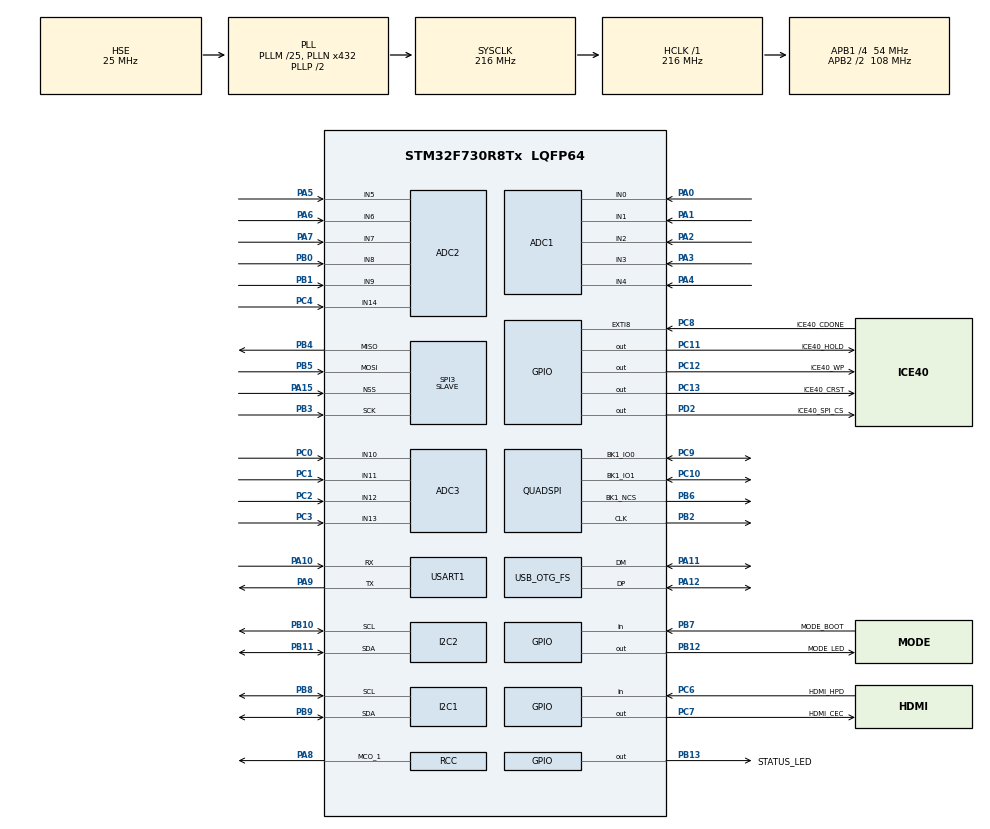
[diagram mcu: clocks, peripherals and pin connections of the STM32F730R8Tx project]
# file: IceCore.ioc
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ADC1.Channel-0\#ChannelRegularConversion=ADC_CHANNEL_0
ADC1.NbrOfConversionFlag=1
ADC1.Rank-0\#ChannelRegularConversion=1
ADC1.SamplingTime-0\#ChannelRegularConversion=ADC_SAMPLETIME_3CYCLES
ADC1.master=1
ADC2.Channel-6\#ChannelRegularConversion=ADC_CHANNEL_5
ADC2.NbrOfConversionFlag=1
ADC2.Rank-6\#ChannelRegularConversion=1
ADC2.SamplingTime-6\#ChannelRegularConversion=ADC_SAMPLETIME_3CYCLES
ADC3.Channel-0\#ChannelRegularConversion=ADC_CHANNEL_13
ADC3.NbrOfConversionFlag=1
ADC3.Rank-0\#ChannelRegularConversion=1
ADC3.SamplingTime-0\#ChannelRegularConversion=ADC_SAMPLETIME_3CYCLES
Dma.Request0=USART1_TX
Dma.USART1_TX.0.Direction=DMA_MEMORY_TO_PERIPH
Dma.USART1_TX.0.FIFOMode=DMA_FIFOMODE_DISABLE
Dma.USART1_TX.0.Instance=DMA2_Stream7
Dma.USART1_TX.0.MemDataAlignment=DMA_MDATAALIGN_BYTE
Dma.USART1_TX.0.MemInc=DMA_MINC_ENABLE
Dma.USART1_TX.0.Mode=DMA_NORMAL
Dma.USART1_TX.0.PeriphDataAlignment=DMA_PDATAALIGN_BYTE
Dma.USART1_TX.0.PeriphInc=DMA_PINC_DISABLE
Dma.USART1_TX.0.Priority=DMA_PRIORITY_LOW
I2C1.Timing=0x20404768
I2C2.Timing=0x20404768
Mcu.Family=STM32F7
Mcu.Name=STM32F730R8Tx
Mcu.Package=LQFP64
NVIC.DMA2_Stream7_IRQn=true\:1\:0\:true\:false\:true\:false
NVIC.OTG_FS_IRQn=true\:1\:0\:true\:false\:true\:false
NVIC.PriorityGroup=NVIC_PRIORITYGROUP_4
NVIC.TIM6_DAC_IRQn=true\:1\:0\:true\:false\:true\:true
NVIC.USART1_IRQn=true\:1\:0\:true\:false\:true\:true
PA0-WKUP.Signal=ADCx_IN0
PA1.Signal=ADCx_IN1
PA10.Mode=Asynchronous
PA10.Signal=USART1_RX
PA11.Mode=Device_Only
PA11.Signal=USB_OTG_FS_DM
PA12.Mode=Device_Only
PA12.Signal=USB_OTG_FS_DP
PA13.Mode=Serial_Wire
PA13.Signal=SYS_JTMS-SWDIO
PA14.Mode=Serial_Wire
PA14.Signal=SYS_JTCK-SWCLK
PA15.Mode=NSS_Signal_Hard_Input
PA15.Signal=SPI3_NSS
PA2.Signal=ADCx_IN2
PA3.Signal=ADCx_IN3
PA4.Signal=ADCx_IN4
PA5.Signal=ADCx_IN5
PA6.Signal=ADCx_IN6
PA7.Signal=ADCx_IN7
PA8.Mode=Clock-out-1
PA8.Signal=RCC_MCO_1
PA9.Mode=Asynchronous
PA9.Signal=USART1_TX
PB0.Signal=ADCx_IN8
PB1.Signal=ADCx_IN9
PB10.Mode=I2C
PB10.Signal=I2C2_SCL
PB11.Mode=I2C
PB11.Signal=I2C2_SDA
PB12.GPIO_Label=MODE_LED
PB12.Signal=GPIO_Output
PB13.GPIO_Label=STATUS_LED
PB13.Signal=GPIO_Output
PB2.Mode=Single Bank 1 2IOs
PB2.Signal=QUADSPI_CLK
PB3.Mode=Full_Duplex_Slave
PB3.Signal=SPI3_SCK
PB4.Mode=Full_Duplex_Slave
PB4.Signal=SPI3_MISO
PB5.Mode=Full_Duplex_Slave
PB5.Signal=SPI3_MOSI
PB6.Mode=Single Bank 1 2IOs
PB6.Signal=QUADSPI_BK1_NCS
PB7.GPIO_Label=MODE_BOOT
PB7.Signal=GPIO_Input
PB8.Mode=I2C
PB8.Signal=I2C1_SCL
PB9.Mode=I2C
PB9.Signal=I2C1_SDA
PC0.Signal=ADCx_IN10
PC1.Signal=ADCx_IN11
PC10.Mode=Single Bank 1 2IOs
PC10.Signal=QUADSPI_BK1_IO1
PC11.GPIO_Label=ICE40_HOLD
PC11.GPIO_ModeDefaultOutputPP=GPIO_MODE_OUTPUT_OD
PC11.Signal=GPIO_Output
PC12.GPIO_Label=ICE40_WP
PC12.GPIO_ModeDefaultOutputPP=GPIO_MODE_OUTPUT_OD
PC12.Signal=GPIO_Output
PC13.GPIO_Label=ICE40_CRST
PC13.Signal=GPIO_Output
PC14-OSC32_IN.Mode=LSE-External-Oscillator
PC14-OSC32_IN.Signal=RCC_OSC32_IN
PC15-OSC32_OUT.Mode=LSE-External-Oscillator
PC15-OSC32_OUT.Signal=RCC_OSC32_OUT
PC2.Signal=ADCx_IN12
PC3.Signal=ADCx_IN13
PC4.Signal=ADCx_IN14
PC6.GPIO_Label=HDMI_HPD
PC6.GPIO_PuPd=GPIO_PULLDOWN
PC6.Signal=GPIO_Input
PC7.GPIO_Label=HDMI_CEC
PC7.Signal=GPIO_Output
PC8.GPIO_Label=ICE40_CDONE
PC8.GPIO_ModeDefaultEXTI=GPIO_MODE_IT_RISING_FALLING
PC8.Signal=GPXTI8
PC9.Mode=Single Bank 1 2IOs
PC9.Signal=QUADSPI_BK1_IO0
PD2.GPIO_Label=ICE40_SPI_CS
PD2.GPIO_ModeDefaultOutputPP=GPIO_MODE_OUTPUT_OD
PD2.Signal=GPIO_Output
PH0-OSC_IN.Mode=HSE-External-Oscillator
PH0-OSC_IN.Signal=RCC_OSC_IN
PH1-OSC_OUT.Mode=HSE-External-Oscillator
PH1-OSC_OUT.Signal=RCC_OSC_OUT
ProjectManager.HeapSize=0x000
ProjectManager.StackSize=0x400
ProjectManager.TargetToolchain=Makefile
QUADSPI.ClockPrescaler=2
RCC.AHBFreq_Value=216000000
RCC.APB1CLKDivider=RCC_HCLK_DIV4
RCC.APB1Freq_Value=54000000
RCC.APB1TimFreq_Value=108000000
RCC.APB2CLKDivider=RCC_HCLK_DIV2
RCC.APB2Freq_Value=108000000
RCC.APB2TimFreq_Value=216000000
RCC.CortexFreq_Value=216000000
RCC.HCLKFreq_Value=216000000
RCC.HSE_VALUE=25000000
RCC.HSI_VALUE=16000000
RCC.PLLM=25
RCC.PLLN=432
RCC.PLLQ=9
RCC.RCC_MCO1Source=RCC_MCO1SOURCE_HSE
RCC.SYSCLKFreq_VALUE=216000000
RCC.SYSCLKSource=RCC_SYSCLKSOURCE_PLLCLK
RCC.USBFreq_Value=48000000
RCC.VCOOutputFreq_Value=432000000
SH.ADCx_IN0.0=ADC1_IN0,IN0
SH.ADCx_IN1.0=ADC1_IN1,IN1
SH.ADCx_IN10.0=ADC3_IN10,IN10
SH.ADCx_IN11.0=ADC3_IN11,IN11
SH.ADCx_IN12.0=ADC3_IN12,IN12
SH.ADCx_IN13.0=ADC3_IN13,IN13
SH.ADCx_IN14.0=ADC2_IN14,IN14
SH.ADCx_IN2.0=ADC1_IN2,IN2
SH.ADCx_IN3.0=ADC1_IN3,IN3
SH.ADCx_IN4.0=ADC1_IN4,IN4
SH.ADCx_IN5.0=ADC2_IN5,IN5
SH.ADCx_IN6.0=ADC2_IN6,IN6
SH.ADCx_IN7.0=ADC2_IN7,IN7
SH.ADCx_IN8.0=ADC2_IN8,IN8
SH.ADCx_IN9.0=ADC2_IN9,IN9
SPI3.DataSize=SPI_DATASIZE_8BIT
SPI3.Direction=SPI_DIRECTION_2LINES
SPI3.Mode=SPI_MODE_SLAVE
SPI3.VirtualNSS=VM_NSSHARD
SPI3.VirtualType=VM_SLAVE
TIM6.AutoReloadPreload=TIM_AUTORELOAD_PRELOAD_ENABLE
TIM6.Period=20000
TIM6.Prescaler=7
USART1.VirtualMode-Asynchronous=VM_ASYNC
USB_DEVICE.CLASS_NAME_FS=CDC
USB_DEVICE.CLASS_NAME_HS=CDC
USB_DEVICE.VirtualMode-CDC_FS=Cdc
USB_DEVICE.VirtualMode-CDC_HS=Cdc
USB_DEVICE.VirtualModeFS=Cdc_FS
USB_DEVICE.VirtualModeHS=Cdc_HS
USB_OTG_FS.VirtualMode=Device_Only
VP_CRC_VS_CRC.Mode=CRC_Activate
VP_RTC_VS_RTC_Activate.Mode=RTC_Enabled
VP_RTC_VS_RTC_Calendar.Mode=RTC_Calendar
VP_TIM6_VS_ClockSourceINT.Mode=Enable_Timer
VP_USB_DEVICE_VS_USB_DEVICE_CDC_FS.Mode=CDC_FS
board=custom

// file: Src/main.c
/* USER CODE BEGIN Header */
/**
  ******************************************************************************
  * @file           : main.c
  * @brief          : Main program body
  ******************************************************************************
  ** This notice applies to any and all portions of this file
  * that are not between comment pairs USER CODE BEGIN and
  * USER CODE END. Other portions of this file, whether
  * inserted by the user or by software development tools
  * are owned by their respective copyright owners.
  *
  * COPYRIGHT(c) 2019 STMicroelectronics
  *
  * Redistribution and use in source and binary forms, with or without modification,
  * are permitted provided that the following conditions are met:
  *   1. Redistributions of source code must retain the above copyright notice,
  *      this list of conditions and the following disclaimer.
  *   2. Redistributions in binary form must reproduce the above copyright notice,
  *      this list of conditions and the following disclaimer in the documentation
  *      and/or other materials provided with the distribution.
  *   3. Neither the name of STMicroelectronics nor the names of its contributors
  *      may be used to endorse or promote products derived from this software
  *      without specific prior written permission.
  *
  * THIS SOFTWARE IS PROVIDED BY THE COPYRIGHT HOLDERS AND CONTRIBUTORS "AS IS"
  * AND ANY EXPRESS OR IMPLIED WARRANTIES, INCLUDING, BUT NOT LIMITED TO, THE
  * IMPLIED WARRANTIES OF MERCHANTABILITY AND FITNESS FOR A PARTICULAR PURPOSE ARE
  * DISCLAIMED. IN NO EVENT SHALL THE COPYRIGHT HOLDER OR CONTRIBUTORS BE LIABLE
  * FOR ANY DIRECT, INDIRECT, INCIDENTAL, SPECIAL, EXEMPLARY, OR CONSEQUENTIAL
  * DAMAGES (INCLUDING, BUT NOT LIMITED TO, PROCUREMENT OF SUBSTITUTE GOODS OR
  * SERVICES; LOSS OF USE, DATA, OR PROFITS; OR BUSINESS INTERRUPTION) HOWEVER
  * CAUSED AND ON ANY THEORY OF LIABILITY, WHETHER IN CONTRACT, STRICT LIABILITY,
  * OR TORT (INCLUDING NEGLIGENCE OR OTHERWISE) ARISING IN ANY WAY OUT OF THE USE
  * OF THIS SOFTWARE, EVEN IF ADVISED OF THE POSSIBILITY OF SUCH DAMAGE.
  *
  ******************************************************************************
  */
/* USER CODE END Header */

#include "main.h"
#include "usb_device.h"

ADC_HandleTypeDef hadc1;
ADC_HandleTypeDef hadc2;
ADC_HandleTypeDef hadc3;

CRC_HandleTypeDef hcrc;

I2C_HandleTypeDef hi2c1;
I2C_HandleTypeDef hi2c2;

QSPI_HandleTypeDef hqspi;

RTC_HandleTypeDef hrtc;

SPI_HandleTypeDef hspi3;

TIM_HandleTypeDef htim6;

UART_HandleTypeDef huart1;

PCD_HandleTypeDef hpcd_USB_OTG_HS;

void SystemClock_Config(void);
static void MX_GPIO_Init(void);
static void MX_USB_OTG_HS_PCD_Init(void);
static void MX_QUADSPI_Init(void);
static void MX_CRC_Init(void);
static void MX_I2C1_Init(void);
static void MX_ADC1_Init(void);
static void MX_ADC2_Init(void);
static void MX_ADC3_Init(void);
static void MX_SPI3_Init(void);
static void MX_USART1_UART_Init(void);
static void MX_I2C2_Init(void);
static void MX_RTC_Init(void);
static void MX_TIM6_Init(void);
/* USER CODE BEGIN PFP */
/* Private function prototypes -----------------------------------------------*/
extern void setup(void);
extern void loop(void);
/* USER CODE END PFP */

int main(void)
{

  /* MCU Configuration--------------------------------------------------------*/

  /* Reset of all peripherals, Initializes the Flash interface and the Systick. */
  HAL_Init();

  /* Configure the system clock */
  SystemClock_Config();

  /* Initialize all configured peripherals */
  MX_GPIO_Init();
  MX_USB_OTG_HS_PCD_Init();
  MX_QUADSPI_Init();
  MX_CRC_Init();
  MX_I2C1_Init();
  MX_ADC1_Init();
  MX_ADC2_Init();
  MX_ADC3_Init();
  MX_SPI3_Init();
  MX_USART1_UART_Init();
  MX_I2C2_Init();
  MX_USB_DEVICE_Init();
  MX_RTC_Init();
  MX_TIM6_Init();
  /* USER CODE BEGIN 2 */
  setup();
  /* USER CODE END 2 */

  /* Infinite loop */
  while (1)
  {

  }
}

void SystemClock_Config(void)
{
  RCC_OscInitTypeDef RCC_OscInitStruct = {0};
  RCC_ClkInitTypeDef RCC_ClkInitStruct = {0};
  RCC_PeriphCLKInitTypeDef PeriphClkInitStruct = {0};

  /**Configure LSE Drive Capability
  */
  HAL_PWR_EnableBkUpAccess();
  /**Configure the main internal regulator output voltage
  */
  __HAL_RCC_PWR_CLK_ENABLE();
  __HAL_PWR_VOLTAGESCALING_CONFIG(PWR_REGULATOR_VOLTAGE_SCALE1);
  /**Initializes the CPU, AHB and APB busses clocks
  */
  RCC_OscInitStruct.OscillatorType = RCC_OSCILLATORTYPE_LSI|RCC_OSCILLATORTYPE_HSE;
  RCC_OscInitStruct.HSEState = RCC_HSE_ON;
  RCC_OscInitStruct.LSIState = RCC_LSI_ON;
  RCC_OscInitStruct.PLL.PLLState = RCC_PLL_ON;
  RCC_OscInitStruct.PLL.PLLSource = RCC_PLLSOURCE_HSE;
  RCC_OscInitStruct.PLL.PLLM = 25;
  RCC_OscInitStruct.PLL.PLLN = 432;
  RCC_OscInitStruct.PLL.PLLP = RCC_PLLP_DIV2;
  RCC_OscInitStruct.PLL.PLLQ = 9;
  if (HAL_RCC_OscConfig(&RCC_OscInitStruct) != HAL_OK)
  {
    Error_Handler();
  }
  /**Activate the Over-Drive mode
  */
  if (HAL_PWREx_EnableOverDrive() != HAL_OK)
  {
    Error_Handler();
  }
  /**Initializes the CPU, AHB and APB busses clocks
  */
  RCC_ClkInitStruct.ClockType = RCC_CLOCKTYPE_HCLK|RCC_CLOCKTYPE_SYSCLK
                              |RCC_CLOCKTYPE_PCLK1|RCC_CLOCKTYPE_PCLK2;
  RCC_ClkInitStruct.SYSCLKSource = RCC_SYSCLKSOURCE_PLLCLK;
  RCC_ClkInitStruct.AHBCLKDivider = RCC_SYSCLK_DIV1;
  RCC_ClkInitStruct.APB1CLKDivider = RCC_HCLK_DIV4;
  RCC_ClkInitStruct.APB2CLKDivider = RCC_HCLK_DIV2;

  if (HAL_RCC_ClockConfig(&RCC_ClkInitStruct, FLASH_LATENCY_7) != HAL_OK)
  {
    Error_Handler();
  }
  PeriphClkInitStruct.PeriphClockSelection = RCC_PERIPHCLK_RTC|RCC_PERIPHCLK_USART1
                              |RCC_PERIPHCLK_I2C1|RCC_PERIPHCLK_I2C2
                              |RCC_PERIPHCLK_CLK48;
  PeriphClkInitStruct.RTCClockSelection = RCC_RTCCLKSOURCE_LSI;
  PeriphClkInitStruct.Usart1ClockSelection = RCC_USART1CLKSOURCE_PCLK2;
  PeriphClkInitStruct.I2c1ClockSelection = RCC_I2C1CLKSOURCE_PCLK1;
  PeriphClkInitStruct.I2c2ClockSelection = RCC_I2C2CLKSOURCE_PCLK1;
  PeriphClkInitStruct.Clk48ClockSelection = RCC_CLK48SOURCE_PLL;
  if (HAL_RCCEx_PeriphCLKConfig(&PeriphClkInitStruct) != HAL_OK)
  {
    Error_Handler();
  }
  HAL_RCC_MCOConfig(RCC_MCO1, RCC_MCO1SOURCE_HSE, RCC_MCODIV_1);
}

static void MX_ADC1_Init(void)
{

  ADC_ChannelConfTypeDef sConfig = {0};

  /**Configure the global features of the ADC (Clock, Resolution, Data Alignment and number of conversion)
  */
  hadc1.Instance = ADC1;
  hadc1.Init.ClockPrescaler = ADC_CLOCK_SYNC_PCLK_DIV4;
  hadc1.Init.Resolution = ADC_RESOLUTION_12B;
  hadc1.Init.ScanConvMode = ADC_SCAN_DISABLE;
  hadc1.Init.ContinuousConvMode = DISABLE;
  hadc1.Init.DiscontinuousConvMode = DISABLE;
  hadc1.Init.ExternalTrigConvEdge = ADC_EXTERNALTRIGCONVEDGE_NONE;
  hadc1.Init.ExternalTrigConv = ADC_SOFTWARE_START;
  hadc1.Init.DataAlign = ADC_DATAALIGN_RIGHT;
  hadc1.Init.NbrOfConversion = 1;
  hadc1.Init.DMAContinuousRequests = DISABLE;
  hadc1.Init.EOCSelection = ADC_EOC_SINGLE_CONV;
  if (HAL_ADC_Init(&hadc1) != HAL_OK)
  {
    Error_Handler();
  }
  /**Configure for the selected ADC regular channel its corresponding rank in the sequencer and its sample time.
  */
  sConfig.Channel = ADC_CHANNEL_0;
  sConfig.Rank = ADC_REGULAR_RANK_1;
  sConfig.SamplingTime = ADC_SAMPLETIME_3CYCLES;
  if (HAL_ADC_ConfigChannel(&hadc1, &sConfig) != HAL_OK)
  {
    Error_Handler();
  }

}

static void MX_ADC2_Init(void)
{

  ADC_ChannelConfTypeDef sConfig = {0};

  /**Configure the global features of the ADC (Clock, Resolution, Data Alignment and number of conversion)
  */
  hadc2.Instance = ADC2;
  hadc2.Init.ClockPrescaler = ADC_CLOCK_SYNC_PCLK_DIV4;
  hadc2.Init.Resolution = ADC_RESOLUTION_12B;
  hadc2.Init.ScanConvMode = ADC_SCAN_DISABLE;
  hadc2.Init.ContinuousConvMode = DISABLE;
  hadc2.Init.DiscontinuousConvMode = DISABLE;
  hadc2.Init.ExternalTrigConvEdge = ADC_EXTERNALTRIGCONVEDGE_NONE;
  hadc2.Init.ExternalTrigConv = ADC_SOFTWARE_START;
  hadc2.Init.DataAlign = ADC_DATAALIGN_RIGHT;
  hadc2.Init.NbrOfConversion = 1;
  hadc2.Init.DMAContinuousRequests = DISABLE;
  hadc2.Init.EOCSelection = ADC_EOC_SINGLE_CONV;
  if (HAL_ADC_Init(&hadc2) != HAL_OK)
  {
    Error_Handler();
  }
  /**Configure for the selected ADC regular channel its corresponding rank in the sequencer and its sample time.
  */
  sConfig.Channel = ADC_CHANNEL_5;
  sConfig.Rank = ADC_REGULAR_RANK_1;
  sConfig.SamplingTime = ADC_SAMPLETIME_3CYCLES;
  if (HAL_ADC_ConfigChannel(&hadc2, &sConfig) != HAL_OK)
  {
    Error_Handler();
  }

}

static void MX_ADC3_Init(void)
{

  ADC_ChannelConfTypeDef sConfig = {0};

  /**Configure the global features of the ADC (Clock, Resolution, Data Alignment and number of conversion)
  */
  hadc3.Instance = ADC3;
  hadc3.Init.ClockPrescaler = ADC_CLOCK_SYNC_PCLK_DIV4;
  hadc3.Init.Resolution = ADC_RESOLUTION_12B;
  hadc3.Init.ScanConvMode = ADC_SCAN_DISABLE;
  hadc3.Init.ContinuousConvMode = DISABLE;
  hadc3.Init.DiscontinuousConvMode = DISABLE;
  hadc3.Init.ExternalTrigConvEdge = ADC_EXTERNALTRIGCONVEDGE_NONE;
  hadc3.Init.ExternalTrigConv = ADC_SOFTWARE_START;
  hadc3.Init.DataAlign = ADC_DATAALIGN_RIGHT;
  hadc3.Init.NbrOfConversion = 1;
  hadc3.Init.DMAContinuousRequests = DISABLE;
  hadc3.Init.EOCSelection = ADC_EOC_SINGLE_CONV;
  if (HAL_ADC_Init(&hadc3) != HAL_OK)
  {
    Error_Handler();
  }
  /**Configure for the selected ADC regular channel its corresponding rank in the sequencer and its sample time.
  */
  sConfig.Channel = ADC_CHANNEL_13;
  sConfig.Rank = ADC_REGULAR_RANK_1;
  sConfig.SamplingTime = ADC_SAMPLETIME_3CYCLES;
  if (HAL_ADC_ConfigChannel(&hadc3, &sConfig) != HAL_OK)
  {
    Error_Handler();
  }

}

static void MX_CRC_Init(void)
{

  hcrc.Instance = CRC;
  hcrc.Init.DefaultPolynomialUse = DEFAULT_POLYNOMIAL_ENABLE;
  hcrc.Init.DefaultInitValueUse = DEFAULT_INIT_VALUE_ENABLE;
  hcrc.Init.InputDataInversionMode = CRC_INPUTDATA_INVERSION_NONE;
  hcrc.Init.OutputDataInversionMode = CRC_OUTPUTDATA_INVERSION_DISABLE;
  hcrc.InputDataFormat = CRC_INPUTDATA_FORMAT_BYTES;
  if (HAL_CRC_Init(&hcrc) != HAL_OK)
  {
    Error_Handler();
  }

}

static void MX_I2C1_Init(void)
{

  hi2c1.Instance = I2C1;
  hi2c1.Init.Timing = 0x20404768;
  hi2c1.Init.OwnAddress1 = 0;
  hi2c1.Init.AddressingMode = I2C_ADDRESSINGMODE_7BIT;
  hi2c1.Init.DualAddressMode = I2C_DUALADDRESS_DISABLE;
  hi2c1.Init.OwnAddress2 = 0;
  hi2c1.Init.OwnAddress2Masks = I2C_OA2_NOMASK;
  hi2c1.Init.GeneralCallMode = I2C_GENERALCALL_DISABLE;
  hi2c1.Init.NoStretchMode = I2C_NOSTRETCH_DISABLE;
  if (HAL_I2C_Init(&hi2c1) != HAL_OK)
  {
    Error_Handler();
  }
  /**Configure Analogue filter
  */
  if (HAL_I2CEx_ConfigAnalogFilter(&hi2c1, I2C_ANALOGFILTER_ENABLE) != HAL_OK)
  {
    Error_Handler();
  }
  /**Configure Digital filter
  */
  if (HAL_I2CEx_ConfigDigitalFilter(&hi2c1, 0) != HAL_OK)
  {
    Error_Handler();
  }

}

static void MX_I2C2_Init(void)
{

  hi2c2.Instance = I2C2;
  hi2c2.Init.Timing = 0x20404768;
  hi2c2.Init.OwnAddress1 = 0;
  hi2c2.Init.AddressingMode = I2C_ADDRESSINGMODE_7BIT;
  hi2c2.Init.DualAddressMode = I2C_DUALADDRESS_DISABLE;
  hi2c2.Init.OwnAddress2 = 0;
  hi2c2.Init.OwnAddress2Masks = I2C_OA2_NOMASK;
  hi2c2.Init.GeneralCallMode = I2C_GENERALCALL_DISABLE;
  hi2c2.Init.NoStretchMode = I2C_NOSTRETCH_DISABLE;
  if (HAL_I2C_Init(&hi2c2) != HAL_OK)
  {
    Error_Handler();
  }
  /**Configure Analogue filter
  */
  if (HAL_I2CEx_ConfigAnalogFilter(&hi2c2, I2C_ANALOGFILTER_ENABLE) != HAL_OK)
  {
    Error_Handler();
  }
  /**Configure Digital filter
  */
  if (HAL_I2CEx_ConfigDigitalFilter(&hi2c2, 0) != HAL_OK)
  {
    Error_Handler();
  }

}

static void MX_QUADSPI_Init(void)
{

  /* QUADSPI parameter configuration*/
  hqspi.Instance = QUADSPI;
  hqspi.Init.ClockPrescaler = 255;
  hqspi.Init.FifoThreshold = 1;
  hqspi.Init.SampleShifting = QSPI_SAMPLE_SHIFTING_NONE;
  hqspi.Init.FlashSize = 1;
  hqspi.Init.ChipSelectHighTime = QSPI_CS_HIGH_TIME_1_CYCLE;
  hqspi.Init.ClockMode = QSPI_CLOCK_MODE_0;
  hqspi.Init.FlashID = QSPI_FLASH_ID_1;
  hqspi.Init.DualFlash = QSPI_DUALFLASH_DISABLE;
  if (HAL_QSPI_Init(&hqspi) != HAL_OK)
  {
    Error_Handler();
  }

}

static void MX_RTC_Init(void)
{

  RTC_TimeTypeDef sTime = {0};
  RTC_DateTypeDef sDate = {0};

  /**Initialize RTC Only
  */
  hrtc.Instance = RTC;
  hrtc.Init.HourFormat = RTC_HOURFORMAT_24;
  hrtc.Init.AsynchPrediv = 127;
  hrtc.Init.SynchPrediv = 255;
  hrtc.Init.OutPut = RTC_OUTPUT_DISABLE;
  hrtc.Init.OutPutPolarity = RTC_OUTPUT_POLARITY_HIGH;
  hrtc.Init.OutPutType = RTC_OUTPUT_TYPE_OPENDRAIN;
  if (HAL_RTC_Init(&hrtc) != HAL_OK)
  {
    Error_Handler();
  }

  /**Initialize RTC and set the Time and Date
  */
  sTime.Hours = 0x0;
  sTime.Minutes = 0x0;
  sTime.Seconds = 0x0;
  sTime.DayLightSaving = RTC_DAYLIGHTSAVING_NONE;
  sTime.StoreOperation = RTC_STOREOPERATION_RESET;
  if (HAL_RTC_SetTime(&hrtc, &sTime, RTC_FORMAT_BCD) != HAL_OK)
  {
    Error_Handler();
  }
  sDate.WeekDay = RTC_WEEKDAY_MONDAY;
  sDate.Month = RTC_MONTH_JANUARY;
  sDate.Date = 0x1;
  sDate.Year = 0x0;

  if (HAL_RTC_SetDate(&hrtc, &sDate, RTC_FORMAT_BCD) != HAL_OK)
  {
    Error_Handler();
  }

}

static void MX_SPI3_Init(void)
{

  /* SPI3 parameter configuration*/
  hspi3.Instance = SPI3;
  hspi3.Init.Mode = SPI_MODE_MASTER;
  hspi3.Init.Direction = SPI_DIRECTION_2LINES;
  hspi3.Init.DataSize = SPI_DATASIZE_4BIT;
  hspi3.Init.CLKPolarity = SPI_POLARITY_LOW;
  hspi3.Init.CLKPhase = SPI_PHASE_1EDGE;
  hspi3.Init.NSS = SPI_NSS_HARD_INPUT;
  hspi3.Init.BaudRatePrescaler = SPI_BAUDRATEPRESCALER_2;
  hspi3.Init.FirstBit = SPI_FIRSTBIT_MSB;
  hspi3.Init.TIMode = SPI_TIMODE_DISABLE;
  hspi3.Init.CRCCalculation = SPI_CRCCALCULATION_DISABLE;
  hspi3.Init.CRCPolynomial = 7;
  hspi3.Init.CRCLength = SPI_CRC_LENGTH_DATASIZE;
  hspi3.Init.NSSPMode = SPI_NSS_PULSE_ENABLE;
  if (HAL_SPI_Init(&hspi3) != HAL_OK)
  {
    Error_Handler();
  }

}

static void MX_TIM6_Init(void)
{

  TIM_MasterConfigTypeDef sMasterConfig = {0};

  htim6.Instance = TIM6;
  htim6.Init.Prescaler = 0;
  htim6.Init.CounterMode = TIM_COUNTERMODE_UP;
  htim6.Init.Period = 0;
  htim6.Init.AutoReloadPreload = TIM_AUTORELOAD_PRELOAD_DISABLE;
  if (HAL_TIM_Base_Init(&htim6) != HAL_OK)
  {
    Error_Handler();
  }
  sMasterConfig.MasterOutputTrigger = TIM_TRGO_RESET;
  sMasterConfig.MasterSlaveMode = TIM_MASTERSLAVEMODE_DISABLE;
  if (HAL_TIMEx_MasterConfigSynchronization(&htim6, &sMasterConfig) != HAL_OK)
  {
    Error_Handler();
  }

}

static void MX_USART1_UART_Init(void)
{

  huart1.Instance = USART1;
  huart1.Init.BaudRate = 115200;
  huart1.Init.WordLength = UART_WORDLENGTH_8B;
  huart1.Init.StopBits = UART_STOPBITS_1;
  huart1.Init.Parity = UART_PARITY_NONE;
  huart1.Init.Mode = UART_MODE_TX_RX;
  huart1.Init.HwFlowCtl = UART_HWCONTROL_NONE;
  huart1.Init.OverSampling = UART_OVERSAMPLING_16;
  huart1.Init.OneBitSampling = UART_ONE_BIT_SAMPLE_DISABLE;
  huart1.AdvancedInit.AdvFeatureInit = UART_ADVFEATURE_NO_INIT;
  if (HAL_UART_Init(&huart1) != HAL_OK)
  {
    Error_Handler();
  }

}

static void MX_USB_OTG_HS_PCD_Init(void)
{

  hpcd_USB_OTG_HS.Instance = USB_OTG_HS;
  hpcd_USB_OTG_HS.Init.dev_endpoints = 9;
  hpcd_USB_OTG_HS.Init.dma_enable = DISABLE;
  hpcd_USB_OTG_HS.Init.ep0_mps = DEP0CTL_MPS_64;
  hpcd_USB_OTG_HS.Init.phy_itface = USB_OTG_ULPI_PHY;
  hpcd_USB_OTG_HS.Init.Sof_enable = DISABLE;
  hpcd_USB_OTG_HS.Init.low_power_enable = DISABLE;
  hpcd_USB_OTG_HS.Init.lpm_enable = DISABLE;
  hpcd_USB_OTG_HS.Init.vbus_sensing_enable = DISABLE;
  hpcd_USB_OTG_HS.Init.use_dedicated_ep1 = DISABLE;
  hpcd_USB_OTG_HS.Init.use_external_vbus = DISABLE;
  if (HAL_PCD_Init(&hpcd_USB_OTG_HS) != HAL_OK)
  {
    Error_Handler();
  }

}

static void MX_GPIO_Init(void)
{
  GPIO_InitTypeDef GPIO_InitStruct = {0};

  /* GPIO Ports Clock Enable */
  __HAL_RCC_GPIOC_CLK_ENABLE();
  __HAL_RCC_GPIOH_CLK_ENABLE();
  __HAL_RCC_GPIOA_CLK_ENABLE();
  __HAL_RCC_GPIOB_CLK_ENABLE();
  __HAL_RCC_GPIOD_CLK_ENABLE();

  /*Configure GPIO pin Output Level */
  HAL_GPIO_WritePin(GPIOC, ICE40_CRST_Pin|HDMI_CEC_Pin|ICE40_HOLD_Pin|ICE40_WP_Pin, GPIO_PIN_RESET);

  /*Configure GPIO pin Output Level */
  HAL_GPIO_WritePin(GPIOB, MODE_LED_Pin|STATUS_LED_Pin, GPIO_PIN_RESET);

  /*Configure GPIO pins : ICE40_CRST_Pin HDMI_CEC_Pin ICE40_HOLD_Pin ICE40_WP_Pin */
  GPIO_InitStruct.Pin = ICE40_CRST_Pin|HDMI_CEC_Pin|ICE40_HOLD_Pin|ICE40_WP_Pin;
  GPIO_InitStruct.Mode = GPIO_MODE_OUTPUT_PP;
  GPIO_InitStruct.Pull = GPIO_NOPULL;
  GPIO_InitStruct.Speed = GPIO_SPEED_FREQ_LOW;
  HAL_GPIO_Init(GPIOC, &GPIO_InitStruct);

  /*Configure GPIO pins : MODE_LED_Pin STATUS_LED_Pin */
  GPIO_InitStruct.Pin = MODE_LED_Pin|STATUS_LED_Pin;
  GPIO_InitStruct.Mode = GPIO_MODE_OUTPUT_PP;
  GPIO_InitStruct.Pull = GPIO_NOPULL;
  GPIO_InitStruct.Speed = GPIO_SPEED_FREQ_LOW;
  HAL_GPIO_Init(GPIOB, &GPIO_InitStruct);

  /*Configure GPIO pins : HDMI_HPD_Pin ICE40_CDONE_Pin */
  GPIO_InitStruct.Pin = HDMI_HPD_Pin|ICE40_CDONE_Pin;
  GPIO_InitStruct.Mode = GPIO_MODE_INPUT;
  GPIO_InitStruct.Pull = GPIO_NOPULL;
  HAL_GPIO_Init(GPIOC, &GPIO_InitStruct);

  /*Configure GPIO pin : PA8 */
  GPIO_InitStruct.Pin = GPIO_PIN_8;
  GPIO_InitStruct.Mode = GPIO_MODE_AF_PP;
  GPIO_InitStruct.Pull = GPIO_NOPULL;
  GPIO_InitStruct.Speed = GPIO_SPEED_FREQ_LOW;
  GPIO_InitStruct.Alternate = GPIO_AF0_MCO;
  HAL_GPIO_Init(GPIOA, &GPIO_InitStruct);

  /*Configure GPIO pin : ICE40_SPI_CS_Pin */
  GPIO_InitStruct.Pin = ICE40_SPI_CS_Pin;
  GPIO_InitStruct.Mode = GPIO_MODE_INPUT;
  GPIO_InitStruct.Pull = GPIO_NOPULL;
  HAL_GPIO_Init(ICE40_SPI_CS_GPIO_Port, &GPIO_InitStruct);

  /*Configure GPIO pin : MODE_BOOT_Pin */
  GPIO_InitStruct.Pin = MODE_BOOT_Pin;
  GPIO_InitStruct.Mode = GPIO_MODE_INPUT;
  GPIO_InitStruct.Pull = GPIO_NOPULL;
  HAL_GPIO_Init(MODE_BOOT_GPIO_Port, &GPIO_InitStruct);

}

void Error_Handler(void)
{
}

/************************ (C) COPYRIGHT STMicroelectronics *****END OF FILE****/
